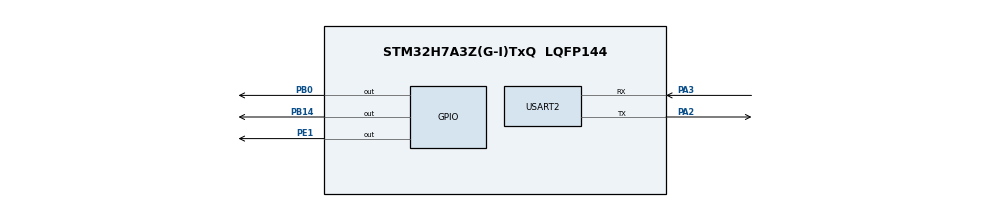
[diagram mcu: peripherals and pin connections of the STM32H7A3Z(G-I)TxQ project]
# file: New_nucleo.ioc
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Mcu.Family=STM32H7
Mcu.Name=STM32H7A3Z(G-I)TxQ
Mcu.Package=LQFP144
NVIC.PriorityGroup=NVIC_PRIORITYGROUP_4
NVIC.USART2_IRQn=true\:0\:0\:false\:false\:true\:true\:true\:true
PA2.Mode=Asynchronous
PA2.Signal=USART2_TX
PA3.Mode=Asynchronous
PA3.Signal=USART2_RX
PB0.Signal=GPIO_Output
PB14.Signal=GPIO_Output
PE1.Signal=GPIO_Output
ProjectManager.HeapSize=0x200
ProjectManager.StackSize=0x400
ProjectManager.TargetToolchain=STM32CubeIDE
RCC.ADCFreq_Value=129000000
RCC.APB1Freq_Value=140000000
RCC.APB2Freq_Value=140000000
RCC.APB3Freq_Value=140000000
RCC.APB4Freq_Value=140000000
RCC.CDPPRE=RCC_APB3_DIV2
RCC.CDPPRE1=RCC_APB1_DIV2
RCC.CDPPRE2=RCC_APB2_DIV2
RCC.CortexFreq_Value=280000000
RCC.DIVM1=4
RCC.DIVM3=1
RCC.DIVN1=35
RCC.DIVN3=24
RCC.DIVQ1=4
RCC.HCLKFreq_Value=280000000
RCC.HSE_VALUE=8000000
RCC.PLLFRACN=0
RCC.PWR_Regulator_Voltage_Scale=PWR_REGULATOR_VOLTAGE_SCALE0
RCC.SRDPPRE=RCC_APB4_DIV2
RCC.SYSCLKFreq_VALUE=280000000
RCC.SYSCLKSource=RCC_SYSCLKSOURCE_PLLCLK
RCC.SupplySource=PWR_DIRECT_SMPS_SUPPLY
RCC.USBCLockSelection=RCC_USBCLKSOURCE_HSI48
RCC.USBFreq_Value=48000000
USART2.VirtualMode-Asynchronous=VM_ASYNC
board=NUCLEO-H7A3ZI-Q

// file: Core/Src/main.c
/* USER CODE BEGIN Header */
/**
  ******************************************************************************
  * @file           : main.c
  * @brief          : Main program body
  ******************************************************************************
  * @attention
  *
  * Copyright (c) 2024 STMicroelectronics.
  * All rights reserved.
  *
  * This software is licensed under terms that can be found in the LICENSE file
  * in the root directory of this software component.
  * If no LICENSE file comes with this software, it is provided AS-IS.
  *
  ******************************************************************************
  */
/* USER CODE END Header */
#include "main.h"
#include "stdio.h"
#include "string.h"

UART_HandleTypeDef huart2;

void SystemClock_Config(void);
static void MX_GPIO_Init(void);
static void MX_USART2_UART_Init(void);

/* USER CODE BEGIN 0 */
uint8_t tx_buffer[100]="Hello from the Nucleo!!!\n\r";
uint8_t rx_buffer[100];
uint8_t rx_indx;
uint8_t rx_data[6];
uint8_t transfer_cplt;
/* USER CODE END 0 */

int main(void)
{

  /* MCU Configuration--------------------------------------------------------*/

  /* Reset of all peripherals, Initializes the Flash interface and the Systick. */
  HAL_Init();

  /* Configure the system clock */
  SystemClock_Config();

  /* Initialize all configured peripherals */
  MX_GPIO_Init();
  MX_USART2_UART_Init();
  /* USER CODE BEGIN 2 */
 // HAL_UART_Receive_IT(&huart2, rx_data, 6);
  /* USER CODE END 2 */

  /* Infinite loop */
  while (1)
  {

    /* USER CODE BEGIN 3 */
	  HAL_UART_Transmit(&huart2, tx_buffer, sizeof(tx_buffer), 10);
	  HAL_Delay(1000);
  }
  /* USER CODE END 3 */
}

void SystemClock_Config(void)
{
  RCC_OscInitTypeDef RCC_OscInitStruct = {0};
  RCC_ClkInitTypeDef RCC_ClkInitStruct = {0};

  /*AXI clock gating */
  RCC->CKGAENR = 0xFFFFFFFF;

  /** Supply configuration update enable
  */
  HAL_PWREx_ConfigSupply(PWR_DIRECT_SMPS_SUPPLY);

  /** Configure the main internal regulator output voltage
  */
  __HAL_PWR_VOLTAGESCALING_CONFIG(PWR_REGULATOR_VOLTAGE_SCALE0);

  while(!__HAL_PWR_GET_FLAG(PWR_FLAG_VOSRDY)) {}

  /** Initializes the RCC Oscillators according to the specified parameters
  * in the RCC_OscInitTypeDef structure.
  */
  RCC_OscInitStruct.OscillatorType = RCC_OSCILLATORTYPE_HSI;
  RCC_OscInitStruct.HSIState = RCC_HSI_DIV1;
  RCC_OscInitStruct.HSICalibrationValue = 64;
  RCC_OscInitStruct.PLL.PLLState = RCC_PLL_ON;
  RCC_OscInitStruct.PLL.PLLSource = RCC_PLLSOURCE_HSI;
  RCC_OscInitStruct.PLL.PLLM = 4;
  RCC_OscInitStruct.PLL.PLLN = 35;
  RCC_OscInitStruct.PLL.PLLP = 2;
  RCC_OscInitStruct.PLL.PLLQ = 4;
  RCC_OscInitStruct.PLL.PLLR = 2;
  RCC_OscInitStruct.PLL.PLLRGE = RCC_PLL1VCIRANGE_3;
  RCC_OscInitStruct.PLL.PLLVCOSEL = RCC_PLL1VCOWIDE;
  RCC_OscInitStruct.PLL.PLLFRACN = 0;
  if (HAL_RCC_OscConfig(&RCC_OscInitStruct) != HAL_OK)
  {
    Error_Handler();
  }

  /** Initializes the CPU, AHB and APB buses clocks
  */
  RCC_ClkInitStruct.ClockType = RCC_CLOCKTYPE_HCLK|RCC_CLOCKTYPE_SYSCLK
                              |RCC_CLOCKTYPE_PCLK1|RCC_CLOCKTYPE_PCLK2
                              |RCC_CLOCKTYPE_D3PCLK1|RCC_CLOCKTYPE_D1PCLK1;
  RCC_ClkInitStruct.SYSCLKSource = RCC_SYSCLKSOURCE_PLLCLK;
  RCC_ClkInitStruct.SYSCLKDivider = RCC_SYSCLK_DIV1;
  RCC_ClkInitStruct.AHBCLKDivider = RCC_HCLK_DIV1;
  RCC_ClkInitStruct.APB3CLKDivider = RCC_APB3_DIV2;
  RCC_ClkInitStruct.APB1CLKDivider = RCC_APB1_DIV2;
  RCC_ClkInitStruct.APB2CLKDivider = RCC_APB2_DIV2;
  RCC_ClkInitStruct.APB4CLKDivider = RCC_APB4_DIV2;

  if (HAL_RCC_ClockConfig(&RCC_ClkInitStruct, FLASH_LATENCY_6) != HAL_OK)
  {
    Error_Handler();
  }
}

static void MX_USART2_UART_Init(void)
{

  huart2.Instance = USART2;
  huart2.Init.BaudRate = 115200;
  huart2.Init.WordLength = UART_WORDLENGTH_8B;
  huart2.Init.StopBits = UART_STOPBITS_1;
  huart2.Init.Parity = UART_PARITY_NONE;
  huart2.Init.Mode = UART_MODE_TX_RX;
  huart2.Init.HwFlowCtl = UART_HWCONTROL_NONE;
  huart2.Init.OverSampling = UART_OVERSAMPLING_16;
  huart2.Init.OneBitSampling = UART_ONE_BIT_SAMPLE_DISABLE;
  huart2.Init.ClockPrescaler = UART_PRESCALER_DIV1;
  huart2.AdvancedInit.AdvFeatureInit = UART_ADVFEATURE_NO_INIT;
  if (HAL_UART_Init(&huart2) != HAL_OK)
  {
    Error_Handler();
  }
  if (HAL_UARTEx_SetTxFifoThreshold(&huart2, UART_TXFIFO_THRESHOLD_1_8) != HAL_OK)
  {
    Error_Handler();
  }
  if (HAL_UARTEx_SetRxFifoThreshold(&huart2, UART_RXFIFO_THRESHOLD_1_8) != HAL_OK)
  {
    Error_Handler();
  }
  if (HAL_UARTEx_DisableFifoMode(&huart2) != HAL_OK)
  {
    Error_Handler();
  }

}

static void MX_GPIO_Init(void)
{
  GPIO_InitTypeDef GPIO_InitStruct = {0};

  /* GPIO Ports Clock Enable */
  __HAL_RCC_GPIOA_CLK_ENABLE();
  __HAL_RCC_GPIOB_CLK_ENABLE();
  __HAL_RCC_GPIOE_CLK_ENABLE();

  /*Configure GPIO pin Output Level */
  HAL_GPIO_WritePin(GPIOB, GPIO_PIN_0|GPIO_PIN_14, GPIO_PIN_RESET);

  /*Configure GPIO pin Output Level */
  HAL_GPIO_WritePin(GPIOE, GPIO_PIN_1, GPIO_PIN_RESET);

  /*Configure GPIO pins : PB0 PB14 */
  GPIO_InitStruct.Pin = GPIO_PIN_0|GPIO_PIN_14;
  GPIO_InitStruct.Mode = GPIO_MODE_OUTPUT_PP;
  GPIO_InitStruct.Pull = GPIO_NOPULL;
  GPIO_InitStruct.Speed = GPIO_SPEED_FREQ_LOW;
  HAL_GPIO_Init(GPIOB, &GPIO_InitStruct);

  /*Configure GPIO pin : PE1 */
  GPIO_InitStruct.Pin = GPIO_PIN_1;
  GPIO_InitStruct.Mode = GPIO_MODE_OUTPUT_PP;
  GPIO_InitStruct.Pull = GPIO_NOPULL;
  GPIO_InitStruct.Speed = GPIO_SPEED_FREQ_LOW;
  HAL_GPIO_Init(GPIOE, &GPIO_InitStruct);

}

/* USER CODE BEGIN 4 */
//void HAL_UART_RxCpltCallback(UART_HandleTypeDef *huart)
//{
// HAL_UART_Transmit(&huart2, rx_data, 6, 10);
//}
/* USER CODE END 4 */

void Error_Handler(void)
{
  __disable_irq();
  while (1)
  {
  }
}
